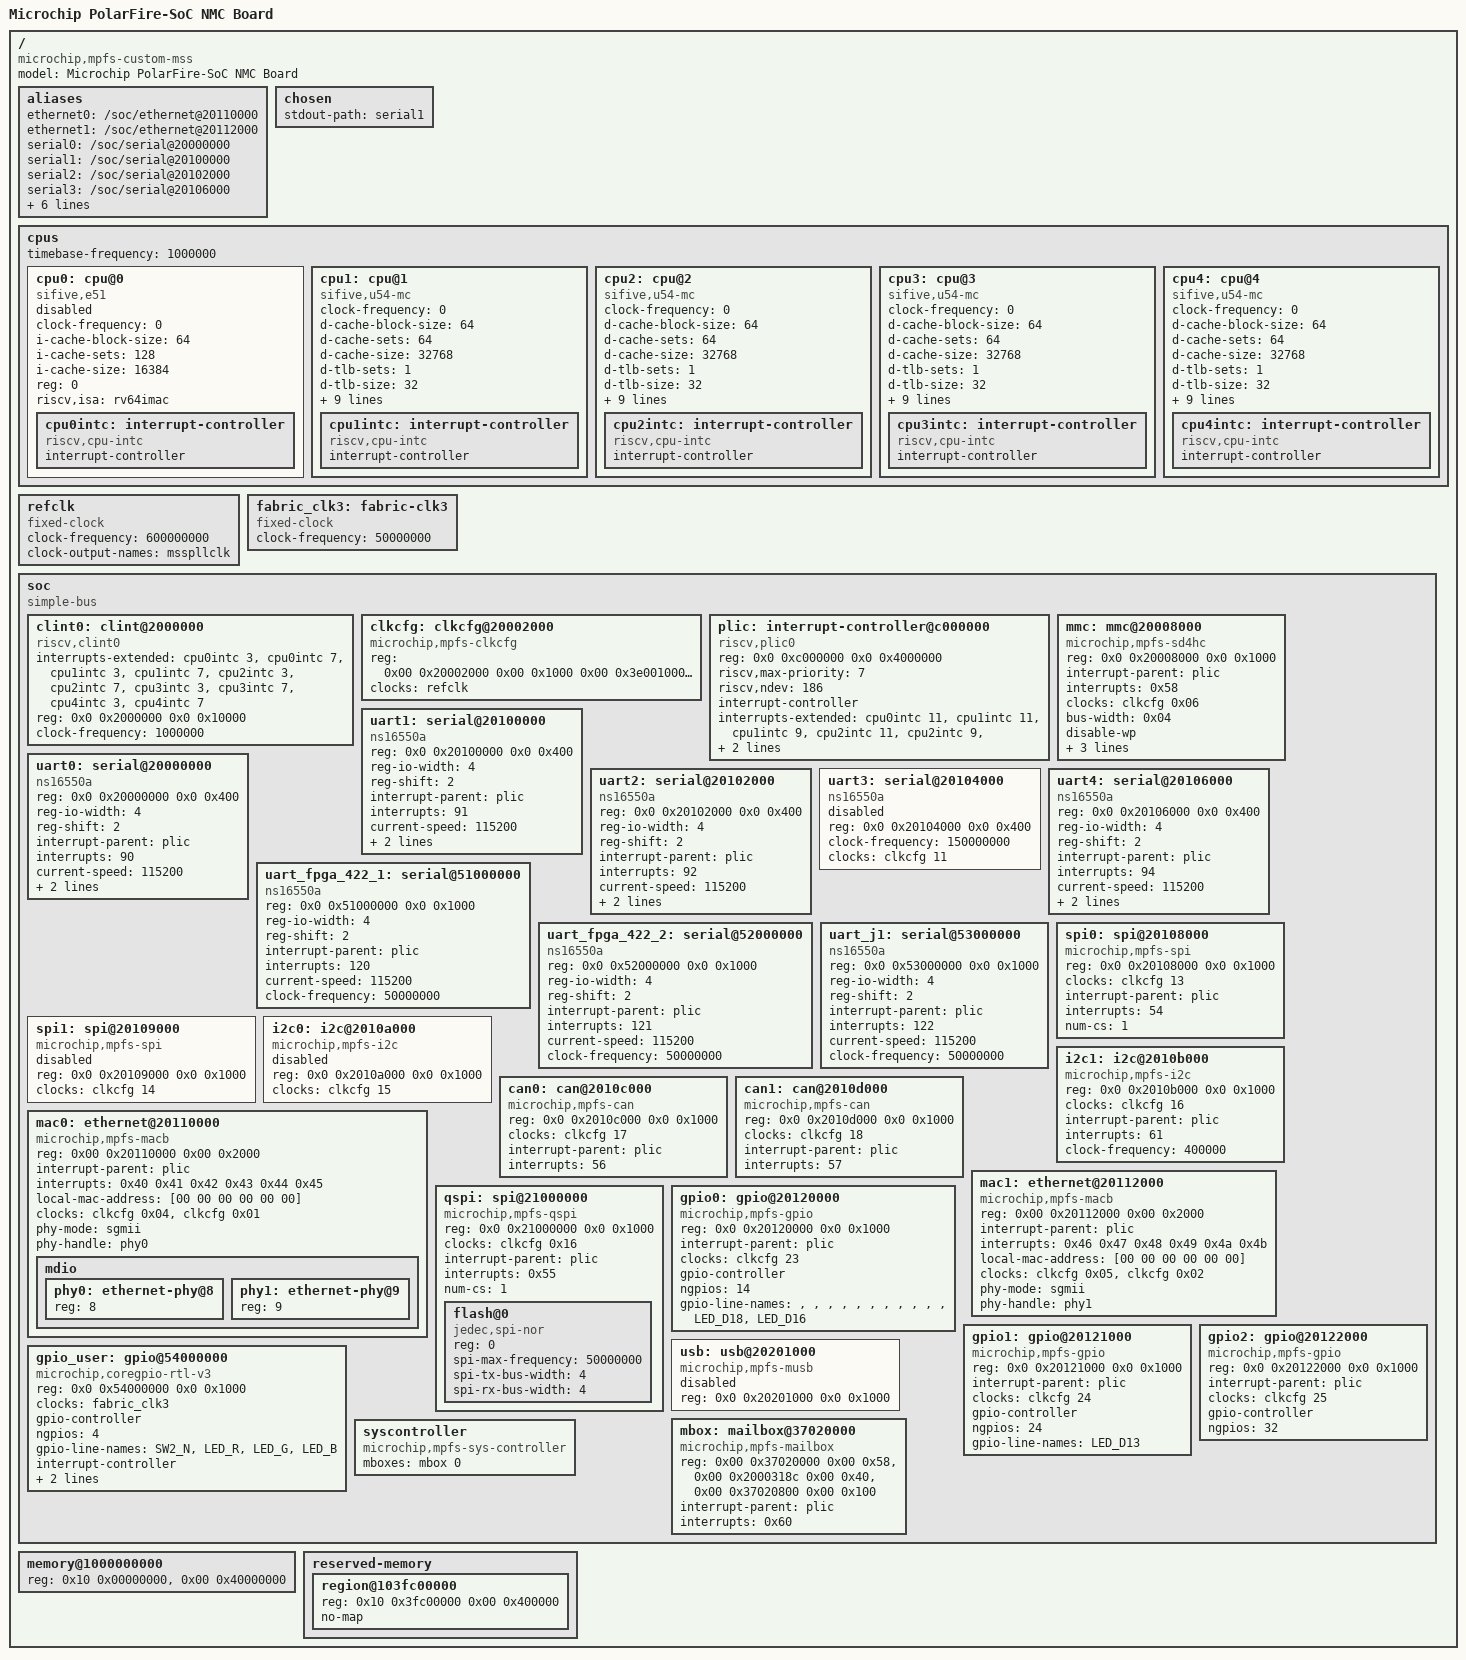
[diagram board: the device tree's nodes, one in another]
/dts-v1/;
//Written by: Andrew Carton 6/1/2026

/ {
	#address-cells = <2>;
	#size-cells = <2>;
	model = "Microchip PolarFire-SoC NMC Board";
	compatible = "microchip,mpfs-custom-mss", "microchip,mpfs";

	/* Same numbering as the Linux DT (ttyS0-ttyS6, can0/can1) */
	aliases {
		ethernet0 = "/soc/ethernet@20110000"; /* MAC_0 */
		ethernet1 = "/soc/ethernet@20112000"; /* MAC_1 */
		serial0 = "/soc/serial@20000000";     /* MMUART_0 */
		serial1 = "/soc/serial@20100000";     /* MMUART_1 (Default Boot Console) */
		serial2 = "/soc/serial@20102000";     /* MMUART_2 */
		serial3 = "/soc/serial@20106000";     /* MMUART_4, RS-422 on J5 */
		serial4 = "/soc/serial@51000000";     /* fabric Core16550, RS-422 on J12 pins 6-9 */
		serial5 = "/soc/serial@52000000";     /* fabric Core16550, RS-422 on J5 E34-E38 */
		serial6 = "/soc/serial@53000000";     /* fabric Core16550, 3.3 V TTL on J1 */
		i2c1 = "/soc/i2c@2010b000";            /* I2C_1 */
		can0 = "/soc/can@2010c000";            /* CAN_0 (via fabric), J12 pins 14/15 */
		can1 = "/soc/can@2010d000";            /* CAN_1 (MSS I/O), J12 pins 11/12 */
	};

	chosen {
		/* No ":115200n8" options: RTEMS looks this up as a plain alias */
		stdout-path = "serial1";
	};

	/* Core nodes (CPUs, CPU clock, CLINT, PLIC) copied verbatim from RTEMS 6.1 bsps/riscv/riscv/dts/mpfs.dts:
	 * the RTEMS BSP looks for these exact compatibles, all 5 harts, and "msspllclk" as the first fixed-clock. */
	cpus {
		#address-cells = <1>;
		#size-cells = <0>;

		timebase-frequency = <1000000>;

		cpu0: cpu@0 {
			clock-frequency = <0>;
			compatible = "sifive,e51", "sifive,rocket0", "riscv";
			device_type = "cpu";
			i-cache-block-size = <64>;
			i-cache-sets = <128>;
			i-cache-size = <16384>;
			reg = <0>;
			riscv,isa = "rv64imac";
			status = "disabled";
			cpu0intc: interrupt-controller {
				#interrupt-cells = <1>;
				compatible = "riscv,cpu-intc";
				interrupt-controller;
			};
		};
		cpu1: cpu@1 {
			clock-frequency = <0>;
			compatible = "sifive,u54-mc", "sifive,rocket0", "riscv";
			d-cache-block-size = <64>;
			d-cache-sets = <64>;
			d-cache-size = <32768>;
			d-tlb-sets = <1>;
			d-tlb-size = <32>;
			device_type = "cpu";
			i-cache-block-size = <64>;
			i-cache-sets = <64>;
			i-cache-size = <32768>;
			i-tlb-sets = <1>;
			i-tlb-size = <32>;
			mmu-type = "riscv,sv39";
			reg = <1>;
			riscv,isa = "rv64imafdc";
			tlb-split;
			status = "okay";
			cpu1intc: interrupt-controller {
				#interrupt-cells = <1>;
				compatible = "riscv,cpu-intc";
				interrupt-controller;
			};
		};

		cpu2: cpu@2 {
			clock-frequency = <0>;
			compatible = "sifive,u54-mc", "sifive,rocket0", "riscv";
			d-cache-block-size = <64>;
			d-cache-sets = <64>;
			d-cache-size = <32768>;
			d-tlb-sets = <1>;
			d-tlb-size = <32>;
			device_type = "cpu";
			i-cache-block-size = <64>;
			i-cache-sets = <64>;
			i-cache-size = <32768>;
			i-tlb-sets = <1>;
			i-tlb-size = <32>;
			mmu-type = "riscv,sv39";
			reg = <2>;
			riscv,isa = "rv64imafdc";
			tlb-split;
			status = "okay";
			cpu2intc: interrupt-controller {
				#interrupt-cells = <1>;
				compatible = "riscv,cpu-intc";
				interrupt-controller;
			};
		};

		cpu3: cpu@3 {
			clock-frequency = <0>;
			compatible = "sifive,u54-mc", "sifive,rocket0", "riscv";
			d-cache-block-size = <64>;
			d-cache-sets = <64>;
			d-cache-size = <32768>;
			d-tlb-sets = <1>;
			d-tlb-size = <32>;
			device_type = "cpu";
			i-cache-block-size = <64>;
			i-cache-sets = <64>;
			i-cache-size = <32768>;
			i-tlb-sets = <1>;
			i-tlb-size = <32>;
			mmu-type = "riscv,sv39";
			reg = <3>;
			riscv,isa = "rv64imafdc";
			tlb-split;
			status = "okay";
			cpu3intc: interrupt-controller {
				#interrupt-cells = <1>;
				compatible = "riscv,cpu-intc";
				interrupt-controller;
			};
		};

		cpu4: cpu@4 {
			clock-frequency = <0>;
			compatible = "sifive,u54-mc", "sifive,rocket0", "riscv";
			d-cache-block-size = <64>;
			d-cache-sets = <64>;
			d-cache-size = <32768>;
			d-tlb-sets = <1>;
			d-tlb-size = <32>;
			device_type = "cpu";
			i-cache-block-size = <64>;
			i-cache-sets = <64>;
			i-cache-size = <32768>;
			i-tlb-sets = <1>;
			i-tlb-size = <32>;
			mmu-type = "riscv,sv39";
			reg = <4>;
			riscv,isa = "rv64imafdc";
			tlb-split;
			status = "okay";
			cpu4intc: interrupt-controller {
				#interrupt-cells = <1>;
				compatible = "riscv,cpu-intc";
				interrupt-controller;
			};
		};
	};

	refclk: refclk {
		compatible = "fixed-clock";
		#clock-cells = <0>;
		clock-frequency = <600000000>;
		clock-output-names = "msspllclk";
	};

	/* Fabric APB clock for the FIC3 peripherals (PF_CCC_C0 OUT3, 50 MHz) */
	fabric_clk3: fabric-clk3 {
		compatible = "fixed-clock";
		#clock-cells = <0>;
		clock-frequency = <50000000>;
	};

	soc {
		#address-cells = <2>;
		#size-cells = <2>;
		compatible = "simple-bus";
		ranges;

		clint0: clint@2000000 {
			compatible = "riscv,clint0";
			interrupts-extended = <&cpu0intc 3 &cpu0intc 7
						&cpu1intc 3 &cpu1intc 7
						&cpu2intc 3 &cpu2intc 7
						&cpu3intc 3 &cpu3intc 7
						&cpu4intc 3 &cpu4intc 7>;
			reg = <0x0 0x2000000 0x0 0x10000>;
			reg-names = "control";
			clock-frequency = <1000000>;
		};

		clkcfg: clkcfg@20002000 {
			compatible = "microchip,mpfs-clkcfg";
			reg = <0x00 0x20002000 0x00 0x1000 0x00 0x3e001000 0x00 0x1000>;
			clocks = <&refclk>;
			#clock-cells = <0x01>;
			#reset-cells = <0x01>;
			phandle = <0x01>;
		};

		plic: interrupt-controller@c000000 {
			#interrupt-cells = <1>;
			compatible = "riscv,plic0";
			reg = <0x0 0xc000000 0x0 0x4000000>;
			riscv,max-priority = <7>;
			riscv,ndev = <186>;
			interrupt-controller;
			interrupts-extended = <
				&cpu0intc 11
				&cpu1intc 11 &cpu1intc 9
				&cpu2intc 11 &cpu2intc 9
				&cpu3intc 11 &cpu3intc 9
				&cpu4intc 11 &cpu4intc 9>;
		};

		/* eMMC Subsystem: 4-bit width, 3.3 V I/O only, High Speed DDR (same as Linux DT) */
		mmc: mmc@20008000 {
			compatible = "microchip,mpfs-sd4hc", "cdns,sd4hc";
			reg = <0x0 0x20008000 0x0 0x1000>;
			interrupt-parent = <&plic>;
			interrupts = <0x58>;
			clocks = <&clkcfg 0x06>;
			bus-width = <0x04>;
			disable-wp;
			no-1-8-v;
			cap-mmc-highspeed;
			mmc-ddr-3_3v;
			status = "okay";
		};

		/*
		 * MMUART_1: Active on Bank2 (Main Boot Console)
		 * Keep this the first ns16550a node: the RTEMS console driver
		 * uses only the first one (RISCV_CONSOLE_MAX_NS16550_DEVICES = 1).
		 */
		uart1: serial@20100000 {
			compatible = "ns16550a";
			reg = <0x0 0x20100000 0x0 0x400>;
			reg-io-width = <4>;
			reg-shift = <2>;
			interrupt-parent = <&plic>;
			interrupts = <91>;
			current-speed = <115200>;
			clock-frequency = <150000000>;
			clocks = <&clkcfg 9>;
			status = "okay";
		};

		/* MMUART_0: Active on Bank2 A */
		uart0: serial@20000000 {
			compatible = "ns16550a";
			reg = <0x0 0x20000000 0x0 0x400>;
			reg-io-width = <4>;
			reg-shift = <2>;
			interrupt-parent = <&plic>;
			interrupts = <90>;
			current-speed = <115200>;
			clock-frequency = <150000000>;
			clocks = <&clkcfg 8>;
			status = "okay";
		};

		/* MMUART_2: Active on Bank2 */
		uart2: serial@20102000 {
			compatible = "ns16550a";
			reg = <0x0 0x20102000 0x0 0x400>;
			reg-io-width = <4>;
			reg-shift = <2>;
			interrupt-parent = <&plic>;
			interrupts = <92>;
			current-speed = <115200>;
			clock-frequency = <150000000>;
			clocks = <&clkcfg 10>;
			status = "okay";
		};

		/* MMUART_3: Disabled */
		uart3: serial@20104000 {
			compatible = "ns16550a";
			reg = <0x0 0x20104000 0x0 0x400>;
			clock-frequency = <150000000>;
			clocks = <&clkcfg 11>;
			status = "disabled";
		};

		/* MMUART_4: Active on Bank2 */
		uart4: serial@20106000 {
			compatible = "ns16550a";
			reg = <0x0 0x20106000 0x0 0x400>;
			reg-io-width = <4>;
			reg-shift = <2>;
			interrupt-parent = <&plic>;
			interrupts = <94>;
			current-speed = <115200>;
			clock-frequency = <150000000>;
			clocks = <&clkcfg 12>;
			status = "okay";
		};

		/* Fabric Core16550 UARTs on FIC3 (50 MHz APB clock) */
		uart_fpga_422_1: serial@51000000 {
			compatible = "ns16550a";
			reg = <0x0 0x51000000 0x0 0x1000>;
			reg-io-width = <4>;
			reg-shift = <2>;
			interrupt-parent = <&plic>;
			interrupts = <120>;
			current-speed = <115200>;
			clock-frequency = <50000000>;
			status = "okay";
		};

		uart_fpga_422_2: serial@52000000 {
			compatible = "ns16550a";
			reg = <0x0 0x52000000 0x0 0x1000>;
			reg-io-width = <4>;
			reg-shift = <2>;
			interrupt-parent = <&plic>;
			interrupts = <121>;
			current-speed = <115200>;
			clock-frequency = <50000000>;
			status = "okay";
		};

		uart_j1: serial@53000000 {
			compatible = "ns16550a";
			reg = <0x0 0x53000000 0x0 0x1000>;
			reg-io-width = <4>;
			reg-shift = <2>;
			interrupt-parent = <&plic>;
			interrupts = <122>;
			current-speed = <115200>;
			clock-frequency = <50000000>;
			status = "okay";
		};

		/* SPI_0: Active Master on Bank 2 */
		spi0: spi@20108000 {
			compatible = "microchip,mpfs-spi";
			reg = <0x0 0x20108000 0x0 0x1000>;
			clocks = <&clkcfg 13>;
			interrupt-parent = <&plic>;
			interrupts = <54>;
			num-cs = <1>;
			#address-cells = <1>;
			#size-cells = <0>;
			status = "okay";
		};

		/* SPI_1: Disabled */
		spi1: spi@20109000 {
			compatible = "microchip,mpfs-spi";
			reg = <0x0 0x20109000 0x0 0x1000>;
			clocks = <&clkcfg 14>;
			status = "disabled";
		};

		/* I2C_0: Disabled */
		i2c0: i2c@2010a000 {
			compatible = "microchip,mpfs-i2c";
			reg = <0x0 0x2010a000 0x0 0x1000>;
			clocks = <&clkcfg 15>;
			status = "disabled";
		};

		/* I2C_1: Active on Bank2 B (Fast Speed 400kHz) */
		i2c1: i2c@2010b000 {
			compatible = "microchip,mpfs-i2c";
			reg = <0x0 0x2010b000 0x0 0x1000>;
			clocks = <&clkcfg 16>;
			interrupt-parent = <&plic>;
			interrupts = <61>;
			#address-cells = <1>;
			#size-cells = <0>;
			clock-frequency = <400000>;
			status = "okay";
		};

		/* CAN_0: routed through the FPGA fabric */
		can0: can@2010c000 {
			compatible = "microchip,mpfs-can";
			reg = <0x0 0x2010c000 0x0 0x1000>;
			clocks = <&clkcfg 17>;
			interrupt-parent = <&plic>;
			interrupts = <56>;
			status = "okay";
		};

		/* CAN_1: MSS I/O */
		can1: can@2010d000 {
			compatible = "microchip,mpfs-can";
			reg = <0x0 0x2010d000 0x0 0x1000>;
			clocks = <&clkcfg 18>;
			interrupt-parent = <&plic>;
			interrupts = <57>;
			status = "okay";
		};

		/* Ethernet Controller 0: Drives the shared MDIO interface */
		mac0: ethernet@20110000 {
			compatible = "microchip,mpfs-macb", "cdns,macb";
			reg = <0x00 0x20110000 0x00 0x2000>;
			interrupt-parent = <&plic>;
			interrupts = <0x40 0x41 0x42 0x43 0x44 0x45>;
			local-mac-address = [00 00 00 00 00 00];
			clocks = <&clkcfg 0x04>, <&clkcfg 0x01>;
			clock-names = "pclk", "hclk";
			status = "okay";
			phy-mode = "sgmii";
			phy-handle = <&phy0>;

			mdio {
				#address-cells = <1>;
				#size-cells = <0>;

				/* CORRECTED: Synchronized node names to match reg numbers */
				phy0: ethernet-phy@8 {
					reg = <8>;
				};

				phy1: ethernet-phy@9 {
					reg = <9>;
				};
			};
		};

		/* Ethernet Controller 1: SGMII Data Plane referencing shared MDIO */
		mac1: ethernet@20112000 {
			compatible = "microchip,mpfs-macb", "cdns,macb";
			reg = <0x00 0x20112000 0x00 0x2000>;
			interrupt-parent = <&plic>;
			interrupts = <0x46 0x47 0x48 0x49 0x4a 0x4b>;
			local-mac-address = [00 00 00 00 00 00];
			clocks = <&clkcfg 0x05>, <&clkcfg 0x02>;
			clock-names = "pclk", "hclk";
			status = "okay";
			phy-mode = "sgmii";
			phy-handle = <&phy1>;
		};

		/* QSPI Subsystem: Active 4-bit NOR Flash (Infineon S25HL01GT) */
		qspi: spi@21000000 {
			compatible = "microchip,mpfs-qspi";
			reg = <0x0 0x21000000 0x0 0x1000>;
			clocks = <&clkcfg 0x16>;
			interrupt-parent = <&plic>;
			interrupts = <0x55>;
			num-cs = <1>;
			#address-cells = <1>;
			#size-cells = <0>;
			status = "okay";

			flash@0 {
				compatible = "jedec,spi-nor";
				reg = <0>;
				spi-max-frequency = <50000000>;
				spi-tx-bus-width = <4>;
				spi-rx-bus-width = <4>;
				status = "okay";
			};
		};

		/* GPIO Controller 0 (Bank 4 Pins Active) */
		gpio0: gpio@20120000 {
			compatible = "microchip,mpfs-gpio";
			reg = <0x0 0x20120000 0x0 0x1000>;
			interrupt-parent = <&plic>;
			clocks = <&clkcfg 23>;
			gpio-controller;
			#gpio-cells = <2>;
			ngpios = <14>;
			/* Green LEDs D18/D16 (GPIO_0_11/12), active low (same names as Linux) */
			gpio-line-names = "", "", "", "", "", "", "", "", "", "", "",
					  "LED_D18", "LED_D16";
			status = "okay";
		};

		/* GPIO Controller 1 (Bank 2 Pins Active) */
		gpio1: gpio@20121000 {
			compatible = "microchip,mpfs-gpio";
			reg = <0x0 0x20121000 0x0 0x1000>;
			interrupt-parent = <&plic>;
			clocks = <&clkcfg 24>;
			gpio-controller;
			#gpio-cells = <2>;
			ngpios = <24>;
			/* Green LED D13 (GPIO_1_0), active low (same name as Linux) */
			gpio-line-names = "LED_D13";
			status = "okay";
		};

		/* GPIO Controller 2: enabled as in Linux (lines 0/1 drive the Ethernet PHY resets) */
		gpio2: gpio@20122000 {
			compatible = "microchip,mpfs-gpio";
			reg = <0x0 0x20122000 0x0 0x1000>;
			interrupt-parent = <&plic>;
			clocks = <&clkcfg 25>;
			gpio-controller;
			#gpio-cells = <2>;
			ngpios = <32>;
			status = "okay";
		};

		/* User GPIO (CoreGPIO, FIC3): SW2 button (in, active low, MSS_INT_F2M[5]),
		 * RGB LED (out, active low: 0 = on). Same as the Linux DT. */
		gpio_user: gpio@54000000 {
			compatible = "microchip,coregpio-rtl-v3";
			reg = <0x0 0x54000000 0x0 0x1000>;
			clocks = <&fabric_clk3>;
			gpio-controller;
			#gpio-cells = <2>;
			ngpios = <4>;
			gpio-line-names = "SW2_N", "LED_R", "LED_G", "LED_B";
			interrupt-controller;
			#interrupt-cells = <2>;
			interrupt-parent = <&plic>;
			interrupts = <123>;
			status = "okay";
		};

		/* USB Host Controller: Disabled */
		usb: usb@20201000 {
			compatible = "microchip,mpfs-musb";
			reg = <0x0 0x20201000 0x0 0x1000>;
			status = "disabled";
		};

		mbox: mailbox@37020000 {
			compatible = "microchip,mpfs-mailbox";
			reg = <0x00 0x37020000 0x00 0x58>, <0x00 0x2000318c 0x00 0x40>, <0x00 0x37020800 0x00 0x100>;
			interrupt-parent = <&plic>;
			interrupts = <0x60>;
			#mbox-cells = <1>;
			status = "okay";
		};

		syscontroller: syscontroller {
			compatible = "microchip,mpfs-sys-controller", "simple-bus";
			#address-cells = <1>;
			#size-cells = <1>;
			mboxes = <&mbox 0>;
			status = "okay";
		};
	};

	/* RTEMS runs from the cached high DDR window (rtems-payload.yaml exec-addr 0x10_0000_0000).
	 * The low window at 0x8000_0000 maps the same physical DDR, so it is not listed again.
	 * 1 GB, same as the HSS linker script for this board (ddrhi). */
	memory@1000000000 {
		device_type = "memory";
		reg = <0x10 0x00000000>, <0x00 0x40000000>;
		status = "okay";
	};

	reserved-memory {
		#address-cells = <2>;
		#size-cells = <2>;
		ranges;

		/* Top 4 MB: where the HSS loads payload.bin (HSS CONFIG_SERVICE_BOOT_DDR_TARGET_ADDR) */
		region@103fc00000 {
			reg = <0x10 0x3fc00000 0x00 0x400000>;
			no-map;
		};
	};
};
